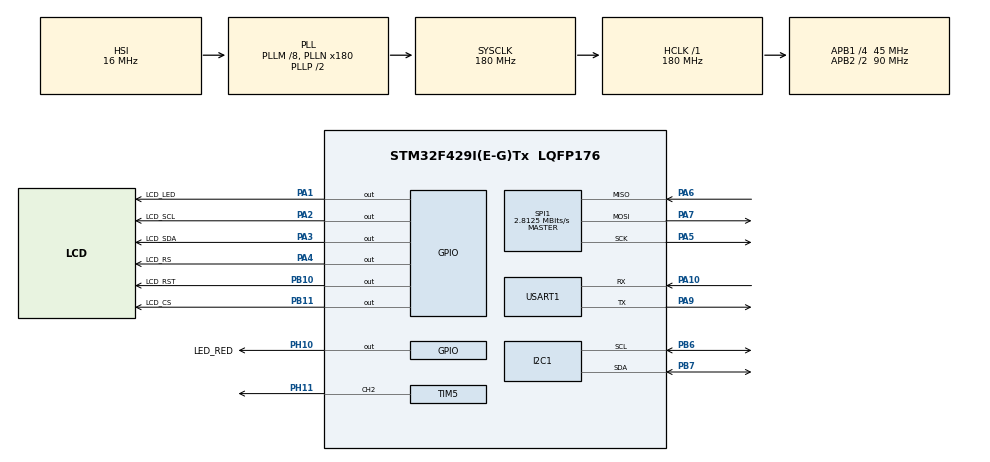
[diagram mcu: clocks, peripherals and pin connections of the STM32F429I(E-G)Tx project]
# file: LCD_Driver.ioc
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Dma.I2C1_RX.3.Direction=DMA_PERIPH_TO_MEMORY
Dma.I2C1_RX.3.FIFOMode=DMA_FIFOMODE_DISABLE
Dma.I2C1_RX.3.Instance=DMA1_Stream0
Dma.I2C1_RX.3.MemDataAlignment=DMA_MDATAALIGN_BYTE
Dma.I2C1_RX.3.MemInc=DMA_MINC_ENABLE
Dma.I2C1_RX.3.Mode=DMA_NORMAL
Dma.I2C1_RX.3.PeriphDataAlignment=DMA_PDATAALIGN_BYTE
Dma.I2C1_RX.3.PeriphInc=DMA_PINC_DISABLE
Dma.I2C1_RX.3.Priority=DMA_PRIORITY_LOW
Dma.I2C1_TX.4.Direction=DMA_MEMORY_TO_PERIPH
Dma.I2C1_TX.4.FIFOMode=DMA_FIFOMODE_DISABLE
Dma.I2C1_TX.4.Instance=DMA1_Stream6
Dma.I2C1_TX.4.MemDataAlignment=DMA_MDATAALIGN_BYTE
Dma.I2C1_TX.4.MemInc=DMA_MINC_ENABLE
Dma.I2C1_TX.4.Mode=DMA_NORMAL
Dma.I2C1_TX.4.PeriphDataAlignment=DMA_PDATAALIGN_BYTE
Dma.I2C1_TX.4.PeriphInc=DMA_PINC_DISABLE
Dma.I2C1_TX.4.Priority=DMA_PRIORITY_LOW
Dma.MEMTOMEM.2.Direction=DMA_MEMORY_TO_MEMORY
Dma.MEMTOMEM.2.FIFOMode=DMA_FIFOMODE_ENABLE
Dma.MEMTOMEM.2.FIFOThreshold=DMA_FIFO_THRESHOLD_FULL
Dma.MEMTOMEM.2.Instance=DMA2_Stream1
Dma.MEMTOMEM.2.MemBurst=DMA_MBURST_SINGLE
Dma.MEMTOMEM.2.MemDataAlignment=DMA_MDATAALIGN_BYTE
Dma.MEMTOMEM.2.MemInc=DMA_MINC_ENABLE
Dma.MEMTOMEM.2.Mode=DMA_NORMAL
Dma.MEMTOMEM.2.PeriphBurst=DMA_PBURST_SINGLE
Dma.MEMTOMEM.2.PeriphDataAlignment=DMA_PDATAALIGN_BYTE
Dma.MEMTOMEM.2.PeriphInc=DMA_PINC_ENABLE
Dma.MEMTOMEM.2.Priority=DMA_PRIORITY_LOW
Dma.Request0=USART1_RX
Dma.Request1=USART1_TX
Dma.Request2=MEMTOMEM
Dma.Request3=I2C1_RX
Dma.Request4=I2C1_TX
Dma.Request5=SPI1_RX
Dma.Request6=SPI1_TX
Dma.SPI1_RX.5.Direction=DMA_PERIPH_TO_MEMORY
Dma.SPI1_RX.5.FIFOMode=DMA_FIFOMODE_DISABLE
Dma.SPI1_RX.5.Instance=DMA2_Stream0
Dma.SPI1_RX.5.MemDataAlignment=DMA_MDATAALIGN_BYTE
Dma.SPI1_RX.5.MemInc=DMA_MINC_ENABLE
Dma.SPI1_RX.5.Mode=DMA_NORMAL
Dma.SPI1_RX.5.PeriphDataAlignment=DMA_PDATAALIGN_BYTE
Dma.SPI1_RX.5.PeriphInc=DMA_PINC_DISABLE
Dma.SPI1_RX.5.Priority=DMA_PRIORITY_LOW
Dma.SPI1_TX.6.Direction=DMA_MEMORY_TO_PERIPH
Dma.SPI1_TX.6.FIFOMode=DMA_FIFOMODE_DISABLE
Dma.SPI1_TX.6.Instance=DMA2_Stream3
Dma.SPI1_TX.6.MemDataAlignment=DMA_MDATAALIGN_BYTE
Dma.SPI1_TX.6.MemInc=DMA_MINC_ENABLE
Dma.SPI1_TX.6.Mode=DMA_NORMAL
Dma.SPI1_TX.6.PeriphDataAlignment=DMA_PDATAALIGN_BYTE
Dma.SPI1_TX.6.PeriphInc=DMA_PINC_DISABLE
Dma.SPI1_TX.6.Priority=DMA_PRIORITY_LOW
Dma.USART1_RX.0.Direction=DMA_PERIPH_TO_MEMORY
Dma.USART1_RX.0.FIFOMode=DMA_FIFOMODE_DISABLE
Dma.USART1_RX.0.Instance=DMA2_Stream2
Dma.USART1_RX.0.MemDataAlignment=DMA_MDATAALIGN_BYTE
Dma.USART1_RX.0.MemInc=DMA_MINC_ENABLE
Dma.USART1_RX.0.Mode=DMA_NORMAL
Dma.USART1_RX.0.PeriphDataAlignment=DMA_PDATAALIGN_BYTE
Dma.USART1_RX.0.PeriphInc=DMA_PINC_DISABLE
Dma.USART1_RX.0.Priority=DMA_PRIORITY_LOW
Dma.USART1_TX.1.Direction=DMA_MEMORY_TO_PERIPH
Dma.USART1_TX.1.FIFOMode=DMA_FIFOMODE_DISABLE
Dma.USART1_TX.1.Instance=DMA2_Stream7
Dma.USART1_TX.1.MemDataAlignment=DMA_MDATAALIGN_BYTE
Dma.USART1_TX.1.MemInc=DMA_MINC_ENABLE
Dma.USART1_TX.1.Mode=DMA_NORMAL
Dma.USART1_TX.1.PeriphDataAlignment=DMA_PDATAALIGN_BYTE
Dma.USART1_TX.1.PeriphInc=DMA_PINC_DISABLE
Dma.USART1_TX.1.Priority=DMA_PRIORITY_LOW
I2C1.I2C_Mode=I2C_Fast
Mcu.Family=STM32F4
Mcu.Name=STM32F429I(E-G)Tx
Mcu.Package=LQFP176
Mcu.UserConstants=OS_TIMER,$$_TIM3_IP_HANDLE_$$;LOG_COM,$$_USART1_IP_HANDLE_$$
NVIC.DMA1_Stream0_IRQn=true\:0\:0\:false\:false\:true\:false\:true\:true
NVIC.DMA1_Stream6_IRQn=true\:0\:0\:false\:false\:true\:false\:true\:true
NVIC.DMA2_Stream0_IRQn=true\:0\:0\:false\:false\:true\:true\:true\:true
NVIC.DMA2_Stream2_IRQn=true\:0\:0\:false\:false\:true\:false\:true\:true
NVIC.DMA2_Stream3_IRQn=true\:0\:0\:false\:false\:true\:false\:true\:true
NVIC.DMA2_Stream7_IRQn=true\:0\:0\:false\:false\:true\:false\:true\:true
NVIC.I2C1_ER_IRQn=true\:0\:0\:false\:false\:true\:true\:true\:true
NVIC.I2C1_EV_IRQn=true\:0\:0\:false\:false\:true\:true\:true\:true
NVIC.PriorityGroup=NVIC_PRIORITYGROUP_4
NVIC.SPI1_IRQn=true\:0\:0\:false\:false\:true\:true\:true\:true
NVIC.TIM3_IRQn=true\:0\:0\:false\:false\:true\:true\:true\:true
NVIC.USART1_IRQn=true\:0\:0\:false\:false\:true\:true\:true\:true
PA1.GPIO_Label=LCD_LED
PA1.GPIO_PuPd=GPIO_PULLUP
PA1.GPIO_Speed=GPIO_SPEED_FREQ_VERY_HIGH
PA1.Signal=GPIO_Output
PA10.Mode=Asynchronous
PA10.Signal=USART1_RX
PA2.GPIO_Label=LCD_SCL
PA2.GPIO_PuPd=GPIO_PULLUP
PA2.GPIO_Speed=GPIO_SPEED_FREQ_VERY_HIGH
PA2.PinState=GPIO_PIN_SET
PA2.Signal=GPIO_Output
PA3.GPIO_Label=LCD_SDA
PA3.GPIO_PuPd=GPIO_PULLUP
PA3.GPIO_Speed=GPIO_SPEED_FREQ_VERY_HIGH
PA3.Signal=GPIO_Output
PA4.GPIO_Label=LCD_RS
PA4.GPIO_PuPd=GPIO_PULLUP
PA4.GPIO_Speed=GPIO_SPEED_FREQ_VERY_HIGH
PA4.Signal=GPIO_Output
PA5.Mode=Full_Duplex_Master
PA5.Signal=SPI1_SCK
PA6.Mode=Full_Duplex_Master
PA6.Signal=SPI1_MISO
PA7.Mode=Full_Duplex_Master
PA7.Signal=SPI1_MOSI
PA9.Mode=Asynchronous
PA9.Signal=USART1_TX
PB10.GPIO_Label=LCD_RST
PB10.GPIO_PuPd=GPIO_PULLUP
PB10.GPIO_Speed=GPIO_SPEED_FREQ_VERY_HIGH
PB10.PinState=GPIO_PIN_SET
PB10.Signal=GPIO_Output
PB11.GPIO_Label=LCD_CS
PB11.GPIO_PuPd=GPIO_PULLUP
PB11.GPIO_Speed=GPIO_SPEED_FREQ_VERY_HIGH
PB11.PinState=GPIO_PIN_SET
PB11.Signal=GPIO_Output
PB6.Mode=I2C
PB6.Signal=I2C1_SCL
PB7.Mode=I2C
PB7.Signal=I2C1_SDA
PH0/OSC_IN.Mode=HSE-External-Oscillator
PH0/OSC_IN.Signal=RCC_OSC_IN
PH1/OSC_OUT.Mode=HSE-External-Oscillator
PH1/OSC_OUT.Signal=RCC_OSC_OUT
PH10.GPIO_Label=LED_RED
PH10.GPIO_PuPd=GPIO_PULLUP
PH10.GPIO_Speed=GPIO_SPEED_FREQ_VERY_HIGH
PH10.PinState=GPIO_PIN_SET
PH10.Signal=GPIO_Output
PH11.Signal=S_TIM5_CH2
ProjectManager.HeapSize=0x200
ProjectManager.StackSize=0x400
ProjectManager.TargetToolchain=STM32CubeIDE
RCC.48MHZClocksFreq_Value=90000000
RCC.AHBFreq_Value=180000000
RCC.APB1CLKDivider=RCC_HCLK_DIV4
RCC.APB1Freq_Value=45000000
RCC.APB1TimFreq_Value=90000000
RCC.APB2CLKDivider=RCC_HCLK_DIV2
RCC.APB2Freq_Value=90000000
RCC.APB2TimFreq_Value=180000000
RCC.CortexFreq_Value=180000000
RCC.HCLKFreq_Value=180000000
RCC.HSE_VALUE=25000000
RCC.HSI_VALUE=16000000
RCC.LSE_VALUE=32768
RCC.PLLM=8
RCC.PLLN=180
RCC.SYSCLKFreq_VALUE=180000000
RCC.SYSCLKSource=RCC_SYSCLKSOURCE_PLLCLK
RCC.VCOOutputFreq_Value=360000000
SH.S_TIM5_CH2.0=TIM5_CH2,PWM Generation2 CH2
SPI1.BaudRatePrescaler=SPI_BAUDRATEPRESCALER_32
SPI1.CLKPhase=SPI_PHASE_2EDGE
SPI1.CLKPolarity=SPI_POLARITY_HIGH
SPI1.CalculateBaudRate=2.8125 MBits/s
SPI1.Direction=SPI_DIRECTION_2LINES
SPI1.Mode=SPI_MODE_MASTER
SPI1.VirtualType=VM_MASTER
TIM3.Period=2000-1
TIM3.Prescaler=900-1
TIM5.Channel-PWM\ Generation2\ CH2=TIM_CHANNEL_2
TIM5.OCFastMode_PWM-PWM\ Generation2\ CH2=TIM_OCFAST_ENABLE
TIM5.OCMode_PWM-PWM\ Generation2\ CH2=TIM_OCMODE_PWM1
TIM5.Period=2000-1
TIM5.Prescaler=900-1
TIM5.Pulse-PWM\ Generation2\ CH2=50
USART1.VirtualMode=VM_ASYNC
VP_TIM3_VS_ClockSourceINT.Mode=Internal
board=custom

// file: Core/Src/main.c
/* USER CODE BEGIN Header */
/**
  ******************************************************************************
  * @file           : main.c
  * @brief          : Main program body
  ******************************************************************************
  * @attention
  *
  * Copyright (c) 2025 STMicroelectronics.
  * All rights reserved.
  *
  * This software is licensed under terms that can be found in the LICENSE file
  * in the root directory of this software component.
  * If no LICENSE file comes with this software, it is provided AS-IS.
  *
  ******************************************************************************
  */
/* USER CODE END Header */
#include "main.h"
#include "dma.h"
#include "i2c.h"
#include "spi.h"
#include "tim.h"
#include "usart.h"
#include "gpio.h"

/* USER CODE BEGIN Includes */
#include "task_bsp.h"
/* USER CODE END Includes */

void SystemClock_Config(void);

int main(void)
{

  /* MCU Configuration--------------------------------------------------------*/

  /* Reset of all peripherals, Initializes the Flash interface and the Systick. */
  HAL_Init();

  /* Configure the system clock */
  SystemClock_Config();

  /* Initialize all configured peripherals */
  MX_GPIO_Init();
  MX_DMA_Init();
  MX_USART1_UART_Init();
  MX_TIM3_Init();
  MX_I2C1_Init();
  MX_TIM5_Init();
  MX_SPI1_Init();
  /* USER CODE BEGIN 2 */
  OS_Init();
  /* USER CODE END 2 */

  /* Infinite loop */
  /* USER CODE BEGIN WHILE */
  while (1)
  {
    Start_OS();
    // Lcd_WriteData(0x55);
    // delay_ms(10);
    // Lcd_WriteData(0x66);
    // delay_ms(10);
    /* USER CODE END WHILE */

  }
}

void SystemClock_Config(void)
{
  RCC_OscInitTypeDef RCC_OscInitStruct = {0};
  RCC_ClkInitTypeDef RCC_ClkInitStruct = {0};

  /** Configure the main internal regulator output voltage
  */
  __HAL_RCC_PWR_CLK_ENABLE();
  __HAL_PWR_VOLTAGESCALING_CONFIG(PWR_REGULATOR_VOLTAGE_SCALE1);

  /** Initializes the RCC Oscillators according to the specified parameters
  * in the RCC_OscInitTypeDef structure.
  */
  RCC_OscInitStruct.OscillatorType = RCC_OSCILLATORTYPE_HSI;
  RCC_OscInitStruct.HSIState = RCC_HSI_ON;
  RCC_OscInitStruct.HSICalibrationValue = RCC_HSICALIBRATION_DEFAULT;
  RCC_OscInitStruct.PLL.PLLState = RCC_PLL_ON;
  RCC_OscInitStruct.PLL.PLLSource = RCC_PLLSOURCE_HSI;
  RCC_OscInitStruct.PLL.PLLM = 8;
  RCC_OscInitStruct.PLL.PLLN = 180;
  RCC_OscInitStruct.PLL.PLLP = RCC_PLLP_DIV2;
  RCC_OscInitStruct.PLL.PLLQ = 4;
  if (HAL_RCC_OscConfig(&RCC_OscInitStruct) != HAL_OK)
  {
    Error_Handler();
  }

  /** Activate the Over-Drive mode
  */
  if (HAL_PWREx_EnableOverDrive() != HAL_OK)
  {
    Error_Handler();
  }

  /** Initializes the CPU, AHB and APB buses clocks
  */
  RCC_ClkInitStruct.ClockType = RCC_CLOCKTYPE_HCLK|RCC_CLOCKTYPE_SYSCLK
                              |RCC_CLOCKTYPE_PCLK1|RCC_CLOCKTYPE_PCLK2;
  RCC_ClkInitStruct.SYSCLKSource = RCC_SYSCLKSOURCE_PLLCLK;
  RCC_ClkInitStruct.AHBCLKDivider = RCC_SYSCLK_DIV1;
  RCC_ClkInitStruct.APB1CLKDivider = RCC_HCLK_DIV4;
  RCC_ClkInitStruct.APB2CLKDivider = RCC_HCLK_DIV2;

  if (HAL_RCC_ClockConfig(&RCC_ClkInitStruct, FLASH_LATENCY_5) != HAL_OK)
  {
    Error_Handler();
  }
}

void Error_Handler(void)
{
  __disable_irq();
  while (1)
  {
  }
}
